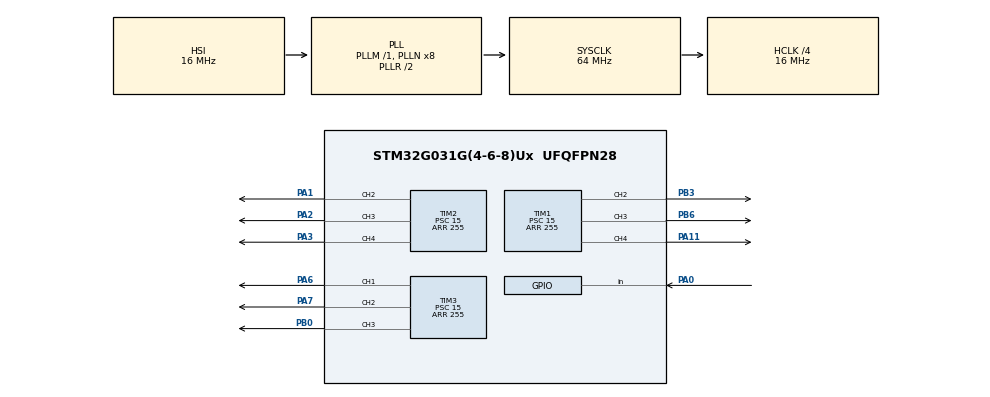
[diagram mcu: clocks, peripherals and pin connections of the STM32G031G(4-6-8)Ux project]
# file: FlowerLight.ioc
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Mcu.Family=STM32G0
Mcu.Name=STM32G031G(4-6-8)Ux
Mcu.Package=UFQFPN28
NVIC.TIM16_IRQn=true\:0\:0\:false\:false\:true\:true\:true\:true
PA0.Signal=GPIO_Input
PA1.Signal=S_TIM2_CH2
PA11\ [PA9].Signal=S_TIM1_CH4
PA13.Mode=Serial_Wire
PA13.Signal=SYS_SWDIO
PA14-BOOT0.Mode=Serial_Wire
PA14-BOOT0.Signal=SYS_SWCLK
PA2.Signal=S_TIM2_CH3
PA3.Signal=S_TIM2_CH4
PA6.Signal=S_TIM3_CH1
PA7.Signal=S_TIM3_CH2
PB0.Signal=S_TIM3_CH3
PB3.Signal=S_TIM1_CH2
PB6.Signal=S_TIM1_CH3
ProjectManager.HeapSize=0x200
ProjectManager.StackSize=0x400
ProjectManager.TargetToolchain=MDK-ARM V5.32
RCC.ADCFreq_Value=64000000
RCC.AHBCLKDivider=RCC_SYSCLK_DIV4
RCC.AHBFreq_Value=16000000
RCC.CortexFreq_Value=16000000
RCC.EXTERNAL_CLOCK_VALUE=12288000
RCC.HCLKFreq_Value=16000000
RCC.HSE_VALUE=8000000
RCC.HSI_VALUE=16000000
RCC.LSE_VALUE=32768
RCC.PLLQ=RCC_PLLQ_DIV4
RCC.SYSCLKFreq_VALUE=64000000
RCC.SYSCLKSource=RCC_SYSCLKSOURCE_PLLCLK
RCC.VCOOutputFreq_Value=128000000
SH.S_TIM1_CH2.0=TIM1_CH2,PWM Generation2 CH2
SH.S_TIM1_CH3.0=TIM1_CH3,PWM Generation3 CH3
SH.S_TIM1_CH4.0=TIM1_CH4,PWM Generation4 CH4
SH.S_TIM2_CH2.0=TIM2_CH2,PWM Generation2 CH2
SH.S_TIM2_CH3.0=TIM2_CH3,PWM Generation3 CH3
SH.S_TIM2_CH4.0=TIM2_CH4,PWM Generation4 CH4
SH.S_TIM3_CH1.0=TIM3_CH1,PWM Generation1 CH1
SH.S_TIM3_CH2.0=TIM3_CH2,PWM Generation2 CH2
SH.S_TIM3_CH3.0=TIM3_CH3,PWM Generation3 CH3
TIM1.Channel-PWM\ Generation2\ CH2=TIM_CHANNEL_2
TIM1.Channel-PWM\ Generation3\ CH3=TIM_CHANNEL_3
TIM1.Channel-PWM\ Generation4\ CH4=TIM_CHANNEL_4
TIM1.Period=255
TIM1.Prescaler=15
TIM16.Period=5 - 1
TIM16.Prescaler=16000 - 1
TIM2.Channel-PWM\ Generation2\ CH2=TIM_CHANNEL_2
TIM2.Channel-PWM\ Generation3\ CH3=TIM_CHANNEL_3
TIM2.Channel-PWM\ Generation4\ CH4=TIM_CHANNEL_4
TIM2.Period=255
TIM2.Prescaler=15
TIM3.Channel-PWM\ Generation1\ CH1=TIM_CHANNEL_1
TIM3.Channel-PWM\ Generation2\ CH2=TIM_CHANNEL_2
TIM3.Channel-PWM\ Generation3\ CH3=TIM_CHANNEL_3
TIM3.Period=255
TIM3.Prescaler=15
VP_TIM16_VS_ClockSourceINT.Mode=Enable_Timer
board=custom

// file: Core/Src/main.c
/* USER CODE BEGIN Header */
/**
  ******************************************************************************
  * @file           : main.c
  * @brief          : Main program body
  ******************************************************************************
  * @attention
  *
  * Copyright (c) 2025 STMicroelectronics.
  * All rights reserved.
  *
  * This software is licensed under terms that can be found in the LICENSE file
  * in the root directory of this software component.
  * If no LICENSE file comes with this software, it is provided AS-IS.
  *
  ******************************************************************************
  */
/* USER CODE END Header */
#include "main.h"
#include "tim.h"
#include "gpio.h"

/* USER CODE BEGIN Includes */
#include "proj.h"
#include "key.h"
/* USER CODE END Includes */

void SystemClock_Config(void);

/* USER CODE BEGIN 0 */
volatile uint8_t ssss;
extern u8 enterStandByModeFlag;
/* USER CODE END 0 */

int main(void)
{

  /* MCU Configuration--------------------------------------------------------*/

  /* Reset of all peripherals, Initializes the Flash interface and the Systick. */
  HAL_Init();

  /* Configure the system clock */
  SystemClock_Config();

  /* Initialize all configured peripherals */
  MX_GPIO_Init();
  MX_TIM1_Init();
  MX_TIM2_Init();
  MX_TIM3_Init();
  MX_TIM16_Init();
  /* USER CODE BEGIN 2 */
  Key_Init();
  Proj_Init();
  // 待机模式相关代码
  __HAL_RCC_PWR_CLK_ENABLE();//使能PWR时钟
    // 检测复位来源
     if (__HAL_PWR_GET_FLAG(PWR_FLAG_SB) != RESET)
     {
         __HAL_PWR_CLEAR_FLAG(PWR_FLAG_SB);
        // 待机唤醒复位
        //  printf("WakeUp from StandBy Mode\r\n");
         enterStandByModeFlag = 0;
     }
  /* USER CODE END 2 */

  /* Infinite loop */
  /* USER CODE BEGIN WHILE */
  while (1)
  {
    Key_Process();
	  Proj_Proc();
    /* USER CODE END WHILE */

  }
}

void SystemClock_Config(void)
{
  RCC_OscInitTypeDef RCC_OscInitStruct = {0};
  RCC_ClkInitTypeDef RCC_ClkInitStruct = {0};

  /** Configure the main internal regulator output voltage
  */
  HAL_PWREx_ControlVoltageScaling(PWR_REGULATOR_VOLTAGE_SCALE1);

  /** Initializes the RCC Oscillators according to the specified parameters
  * in the RCC_OscInitTypeDef structure.
  */
  RCC_OscInitStruct.OscillatorType = RCC_OSCILLATORTYPE_HSI;
  RCC_OscInitStruct.HSIState = RCC_HSI_ON;
  RCC_OscInitStruct.HSIDiv = RCC_HSI_DIV1;
  RCC_OscInitStruct.HSICalibrationValue = RCC_HSICALIBRATION_DEFAULT;
  RCC_OscInitStruct.PLL.PLLState = RCC_PLL_ON;
  RCC_OscInitStruct.PLL.PLLSource = RCC_PLLSOURCE_HSI;
  RCC_OscInitStruct.PLL.PLLM = RCC_PLLM_DIV1;
  RCC_OscInitStruct.PLL.PLLN = 8;
  RCC_OscInitStruct.PLL.PLLP = RCC_PLLP_DIV2;
  RCC_OscInitStruct.PLL.PLLQ = RCC_PLLQ_DIV4;
  RCC_OscInitStruct.PLL.PLLR = RCC_PLLR_DIV2;
  if (HAL_RCC_OscConfig(&RCC_OscInitStruct) != HAL_OK)
  {
    Error_Handler();
  }

  /** Initializes the CPU, AHB and APB buses clocks
  */
  RCC_ClkInitStruct.ClockType = RCC_CLOCKTYPE_HCLK|RCC_CLOCKTYPE_SYSCLK
                              |RCC_CLOCKTYPE_PCLK1;
  RCC_ClkInitStruct.SYSCLKSource = RCC_SYSCLKSOURCE_PLLCLK;
  RCC_ClkInitStruct.AHBCLKDivider = RCC_SYSCLK_DIV4;
  RCC_ClkInitStruct.APB1CLKDivider = RCC_HCLK_DIV1;

  if (HAL_RCC_ClockConfig(&RCC_ClkInitStruct, FLASH_LATENCY_0) != HAL_OK)
  {
    Error_Handler();
  }
}

void Error_Handler(void)
{
  __disable_irq();
  while (1)
  {
  }
}
